# LPC11xxLV_LPC111x_LV register map
File version: 1
CPU: CM0 r0p0, little endian, no MPU, no FPU, 2 interrupt priority bits
Registers are 32-bit, read-write, reset 0x0 unless marked. A register's access mark holds for its fields unless they carry their own. Offsets are from the block's base; [hi:lo] are bit positions; {n}, {i} and the like mark numbered series; 'fields as' and 'values as' point back to an identical list.

## CT32B0 — 32-bit counter/timer CT32B0/1
Base 0x40014000
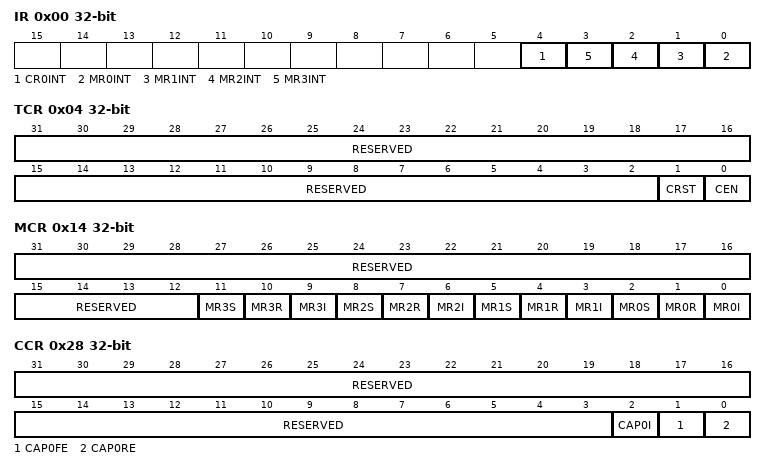
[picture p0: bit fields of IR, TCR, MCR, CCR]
0x00 IR — Interrupt Register (IR). The IR can be written to clear interrupts. The IR can be read to identify which of five possible interrupt sources are pending.
  [4] CR0INT — Interrupt flag for capture channel 0 event.
  [n] MR{n}INT (n=0..3) — Interrupt flag for match channel {n}.
0x04 TCR — Timer Control Register (TCR). The TCR is used to control the Timer Counter functions. The Timer Counter can be disabled or reset through the TCR.
  [31:2] RESERVED — Reserved, user software should not write ones to reserved bits. The value read from a reserved bit is not defined.
  [1] CRST — When one, the Timer Counter and the Prescale Counter are synchronously reset on the next positive edge of PCLK. The counters remain reset until TCR[1] is returned to zero.
  [0] CEN — When one, the Timer Counter and Prescale Counter are enabled for counting. When zero, the counters are disabled.
0x08 TC — Timer Counter (TC). The 32-bit TC is incremented every PR+1 cycles of PCLK. The TC is controlled through the TCR.
  [31:0] TC — Timer counter value.
0x0C PR — Prescale Register (PR). When the Prescale Counter (below) is equal to this value, the next clock increments the TC and clears the PC.
  [31:0] PR — Prescale value.
0x10 PC — Prescale Counter (PC). The 32-bit PC is a counter which is incremented to the value stored in PR. When the value in PR is reached, the TC is incremented and the PC is cleared. The PC is observable and controllable through the bus interface.
  [31:0] PC — Prescale counter value.
0x14 MCR — Match Control Register (MCR). The MCR is used to control if an interrupt is generated and if the TC is reset when a Match occurs.
  [31:12] RESERVED — Reserved, user software should not write ones to reserved bits. The value read from a reserved bit is not defined.
  [3n+2] MR{n}S (n=0..3) — Stop on MR{n}: the TC and PC will be stopped and TCR[0] will be set to 0 if MR{n} matches the TC.
    1=ENABLED; 0=DISABLED
  [3n+1] MR{n}R (n=0..3) — Reset on MR{n}: the TC will be reset if MR{n} matches it.
    1=ENABLED; 0=DISABLED
  [3n] MR{n}I (n=0..3) — Interrupt on MR{n}: an interrupt is generated when MR{n} matches the value in the TC.
    1=ENABLED; 0=DISABLED
{0x18+4i} MR{i} (i=0..3) — Match Register. MR can be enabled through the MCR to reset the TC, stop both the TC and PC, and/or generate an interrupt every time MR matches the TC.
  [31:0] MATCH — Timer counter match value.
0x28 CCR — Capture Control Register (CCR). The CCR controls which edges of the capture inputs are used to load the Capture Registers and whether or not an interrupt is generated when a capture takes place.
  [31:3] RESERVED — Reserved, user software should not write ones to reserved bits. The value read from a reserved bit is not defined.
  [2] CAP0I — Interrupt on CT32Bn_CAP0 event: a CR0 load due to a CT32Bn_CAP0 event will generate an interrupt.
    1=ENABLED; 0=DISABLED
  [1] CAP0FE — Capture on CT32Bn_CAP0 falling edge: a sequence of 1 then 0 on CT32Bn_CAP0 will cause CR0 to be loaded with the contents of TC.
    1=ENABLED; 0=DISABLED
  [0] CAP0RE — Capture on CT32Bn_CAP0 rising edge: a sequence of 0 then 1 on CT32Bn_CAP0 will cause CR0 to be loaded with the contents of TC.
    1=ENABLED; 0=DISABLED
0x2C CR0 ro — Capture Register (CR). CR is loaded with the value of TC when there is an event on the CT32B1_CAP0 input.
  [31:0] CAP — Timer counter capture value.
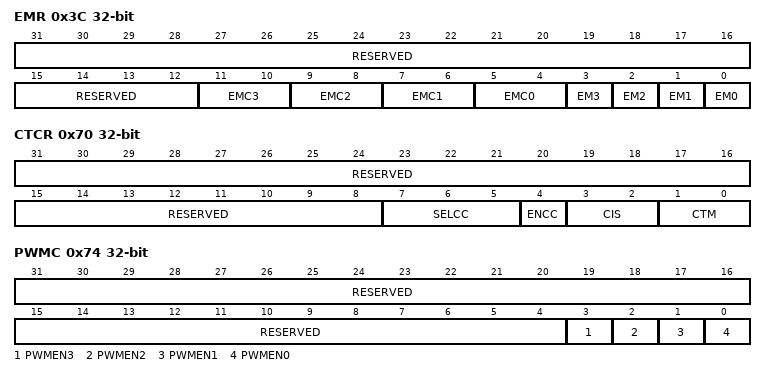
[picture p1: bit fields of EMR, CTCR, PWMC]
0x3C EMR — External Match Register (EMR). The EMR controls the match function and the external match pins CT32B0_MAT[3:0].
  [31:12] RESERVED — Reserved, user software should not write ones to reserved bits. The value read from a reserved bit is not defined.
  [2n+5:2n+4] EMC{n} (n=0..3) — External Match Control {n}. Determines the functionality of External Match {n}.
    0=DO_NOTHING_; 1=CLEAR_THE_CORRESPOND (Clear the corresponding External Match bit/output to 0 (CT32Bn_MATm pin is LOW if pinned out).); 2=SET_THE_CORRESPONDIN (Set the corresponding External Match bit/output to 1 (CT32Bn_MATm pin is HIGH if pinned out).); 3=TOGGLE_THE_CORRESPON (Toggle the corresponding External Match bit/output.)
  [n] EM{n} (n=0..3) — External Match {n}. This bit reflects the state of output CT32Bn_MAT{n}, whether or not this output is connected to its pin. When a match occurs between the TC and MR{n}, this bit can either toggle, go LOW, go HIGH, or do nothing. Bits EMR[{2n+5}:{2n+4}] control the functionality of this output. This bit is driven to the CT32B0_MAT{n}/CT16B1_MAT{n} pins if the match function is selected in the IOCON registers (0 = LOW, 1 = HIGH).
0x70 CTCR — Count Control Register (CTCR). The CTCR selects between Timer and Counter mode, and in Counter mode selects the signal and edge(s) for counting.
  [31:8] RESERVED — Reserved, user software should not write ones to reserved bits. The value read from a reserved bit is not defined.
  [7:5] SELCC — When bit 4 is one, these bits select which capture input edge will cause the timer and prescaler to be cleared. These bits have no effect when bit 4 is zero.
    0=RISING_EDGE_OF_CAP0_ (Rising Edge of CAP0 clears the timer (if bit 4 is set).); 1=FALLING_EDGE_OF_CAP0 (Falling Edge of CAP0 clears the timer (if bit 4 is set).); 2=RISING_EDGE_OF_CAP1_ (Rising Edge of CAP1 clears the timer (if bit 4 is set).); 3=FALLING_EDGE_OF_CAP1 (Falling Edge of CAP1 clears the timer (if bit 4 is set).)
  [4] ENCC — Setting this bit to one enables clearing of the timer and the prescaler when the capture-edge event specified in bits 7:5 occurs.
  [3:2] CIS — Count Input Select. When bits 1:0 in this register are not 00, these bits select which CAP pin is sampled for clocking:
    0=CT32BN_CAP0; 1=CT32BN_CAP1; 3=RESERVED_NOTE_IF_CO (Reserved Note: If Counter mode is selected in the TnCTCR, the 3 bits for that input in the Capture Control Register (TnCCR) must be programmed as 000.)
  [1:0] CTM — Counter/Timer Mode. This field selects which rising PCLK edges can increment Timer's Prescale Counter (PC), or clear PC and increment Timer Counter (TC). Timer Mode: every rising PCLK edge
    0=TIMER_MODE_EVERY_RI (Timer Mode: every rising PCLK edge); 1=COUNTER_MODE_TC_IS_ (Counter Mode: TC is incremented on rising edges on the CAP input selected by bits 3:2.); 2=COUNTER_MODE_TC_IS_ (Counter Mode: TC is incremented on falling edges on the CAP input selected by bits 3:2.); 3=COUNTER_MODE_TC_IS_ (Counter Mode: TC is incremented on both edges on the CAP input selected by bits 3:2.)
0x74 PWMC — PWM Control Register (PWMCON). The PWMCON enables PWM mode for the external match pins CT32B0_MAT[3:0].
  [31:4] RESERVED — Reserved, user software should not write ones to reserved bits. The value read from a reserved bit is not defined.
  [3] PWMEN3 — PWM channel 3 enable Note: It is recommended to use match channel 3 to set the PWM cycle.
    0=CT32BN_MAT3_IS_CONTR (CT32Bn_MAT3 is controlled by EM3.); 1=PWM_MODE_IS_ENABLED_ (PWM mode is enabled for CT32Bn_MAT3.)
  [2] PWMEN2 — PWM channel 2 enable
    0=CT32BN_MAT2_IS_CONTR (CT32Bn_MAT2 is controlled by EM2.); 1=PWM_MODE_IS_ENABLED_ (PWM mode is enabled for CT32Bn_MAT2.)
  [1] PWMEN1 — PWM channel 1 enable
    0=CT32BN_MAT1_IS_CONTR (CT32Bn_MAT1 is controlled by EM1.); 1=PWM_MODE_IS_ENABLED_ (PWM mode is enabled for CT32Bn_MAT1.)
  [0] PWMEN0 — PWM channel 0 enable
    0=CT32BN_MAT0_IS_CONTR (CT32Bn_MAT0 is controlled by EM0.); 1=PWM_MODE_IS_ENABLED_ (PWM mode is enabled for CT32Bn_MAT0.)

## CT32B1 — 32-bit counter/timer CT32B0/1
Base 0x40018000
Registers as CT32B0, without CR0; these are added or differ:
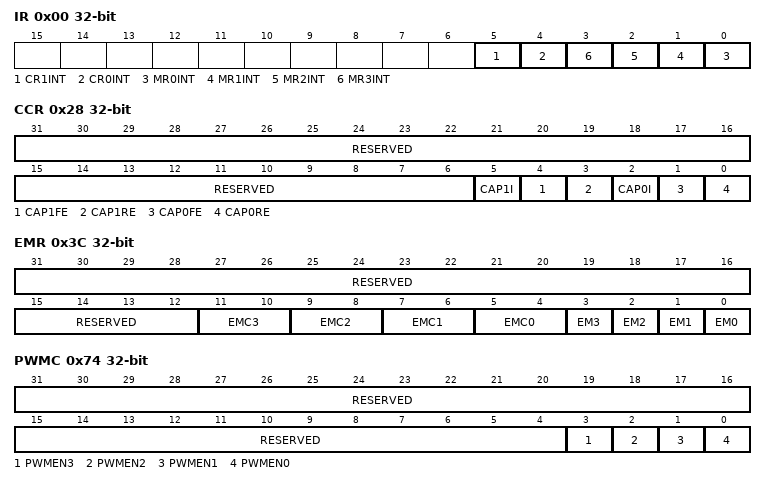
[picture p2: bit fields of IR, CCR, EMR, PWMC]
0x00 IR — Interrupt Register (IR). The IR can be written to clear interrupts. The IR can be read to identify which of five possible interrupt sources are pending.
  [5] CR1INT — Interrupt flag for capture channel 1 event.
  [4] CR0INT — Interrupt flag for capture channel 0 event.
  [n] MR{n}INT (n=0..3) — Interrupt flag for match channel {n}.
0x28 CCR — Capture Control Register (CCR). The CCR controls which edges of the capture inputs are used to load the Capture Registers and whether or not an interrupt is generated when a capture takes place.
  [31:6] RESERVED — Reserved, user software should not write ones to reserved bits. The value read from a reserved bit is not defined.
  [5] CAP1I — Interrupt on CT32Bn_CAP1 event: a CR1 load due to a CT32Bn_CAP1 event will generate an interrupt.
    1=ENABLED; 0=DISABLED
  [4] CAP1FE — Capture on CT32Bn_CAP1 falling edge: a sequence of 1 then 0 on CT32Bn_CAP1 will cause CR1 to be loaded with the contents of TC.
    1=ENABLED; 0=DISABLED
  [3] CAP1RE — Capture on CT32Bn_CAP1 rising edge: a sequence of 0 then 1 on CT32Bn_CAP1 will cause CR1 to be loaded with the contents of TC.
    1=ENABLED; 0=DISABLED
  [2] CAP0I — Interrupt on CT32Bn_CAP0 event: a CR0 load due to a CT32Bn_CAP0 event will generate an interrupt.
    1=ENABLED; 0=DISABLED
  [1] CAP0FE — Capture on CT32Bn_CAP0 falling edge: a sequence of 1 then 0 on CT32Bn_CAP0 will cause CR0 to be loaded with the contents of TC.
    1=ENABLED; 0=DISABLED
  [0] CAP0RE — Capture on CT32Bn_CAP0 rising edge: a sequence of 0 then 1 on CT32Bn_CAP0 will cause CR0 to be loaded with the contents of TC.
    1=ENABLED; 0=DISABLED
{0x2C+4i} CR{i} (i=0..1) ro — Capture Register (CR). CR is loaded with the value of TC when there is an event on the CT32Bn_CAPm input.
  [31:0] CAP — Timer counter capture value.
0x3C EMR — External Match Register (EMR). The EMR controls the match function and the external match pins CT32B0_MAT[3:0].
  fields as CT32B0.EMR
0x74 PWMC — PWM Control Register (PWMCON). The PWMCON enables PWM mode for the external match pins CT32B0_MAT[3:0].
  fields as CT32B0.PWMC
